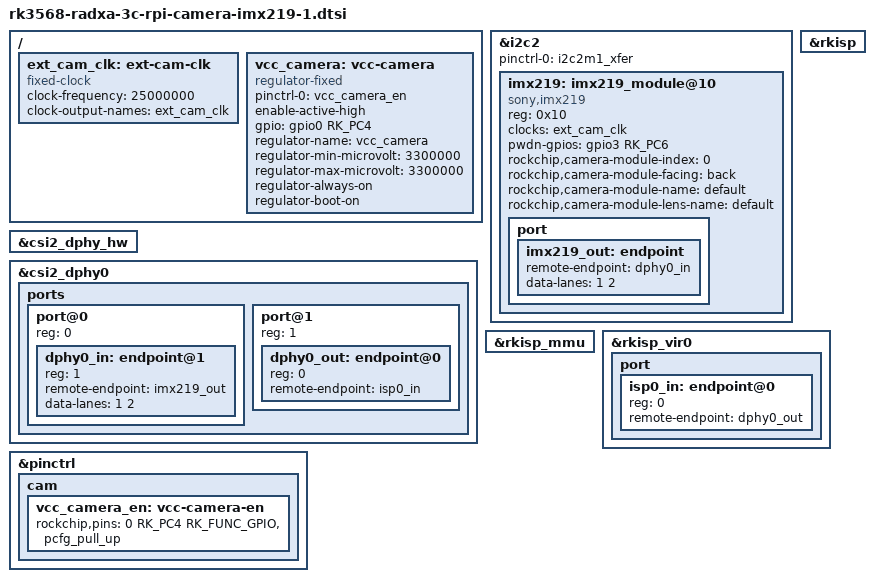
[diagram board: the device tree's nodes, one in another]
// SPDX-License-Identifier: (GPL-2.0+ OR MIT)
/*
 * Copyright (c) 2022 Radxa Limited.
 *
 */

/ {
	ext_cam_clk: ext-cam-clk {
        status = "okay";
        compatible = "fixed-clock";
        clock-frequency = <25000000>;
        clock-output-names = "ext_cam_clk";
        #clock-cells = <0>;
    };

	vcc_camera: vcc-camera {
        status = "okay";
        compatible = "regulator-fixed";
		pinctrl-names = "default";
		pinctrl-0 = <&vcc_camera_en>;
		enable-active-high;
        gpio = <&gpio0 RK_PC4 GPIO_ACTIVE_HIGH>;
		regulator-name = "vcc_camera";
        regulator-min-microvolt = <3300000>;
        regulator-max-microvolt = <3300000>;
        regulator-always-on;
        regulator-boot-on;
    };

};

&i2c2 {

	status = "okay";
    pinctrl-names = "default";
    pinctrl-0 = <&i2c2m1_xfer>;

	imx219: imx219_module@10 {
		compatible = "sony,imx219";
		status = "okay";
		reg = <0x10>;
		clocks = <&ext_cam_clk>;
		clock-names = "ext_cam_clk";

		pinctrl-names = "rockchip,camera_default";
		pwdn-gpios = <&gpio3 RK_PC6 GPIO_ACTIVE_HIGH>;
		rockchip,camera-module-index = <0>;
		rockchip,camera-module-facing = "back";
		rockchip,camera-module-name = "default";
		rockchip,camera-module-lens-name = "default";

		port {
			imx219_out: endpoint {
				remote-endpoint = <&dphy0_in>;
				data-lanes = <1 2>;
			};
		};
	};
};
&csi2_dphy_hw {
	status = "okay";
};

&csi2_dphy0 {
	status = "okay";
/*
* dphy0 only used for full mode,
* full mode and split mode are mutually exclusive
*/
	ports {
		#address-cells = <1>;
		#size-cells = <0>;

		port@0 {
			reg = <0>;
			#address-cells = <1>;
			#size-cells = <0>;

			dphy0_in: endpoint@1 {
				reg = <1>;
				remote-endpoint = <&imx219_out>;
				data-lanes = <1 2>;
			};
		};

		port@1 {
			reg = <1>;
			#address-cells = <1>;
			#size-cells = <0>;

			dphy0_out: endpoint@0 {
				reg = <0>;
				remote-endpoint = <&isp0_in>;
			};
		};
	};
};

&rkisp {
	status = "okay";
};

&rkisp_mmu {
	status = "okay";
};

&rkisp_vir0 {
	status = "okay";

	port {
		#address-cells = <1>;
		#size-cells = <0>;

		isp0_in: endpoint@0 {
			reg = <0>;
			remote-endpoint = <&dphy0_out>;
		};
	};
};

&pinctrl {
	cam {
		vcc_camera_en: vcc-camera-en {
			rockchip,pins =
				<0 RK_PC4 RK_FUNC_GPIO &pcfg_pull_up>;
		};
	};
};
